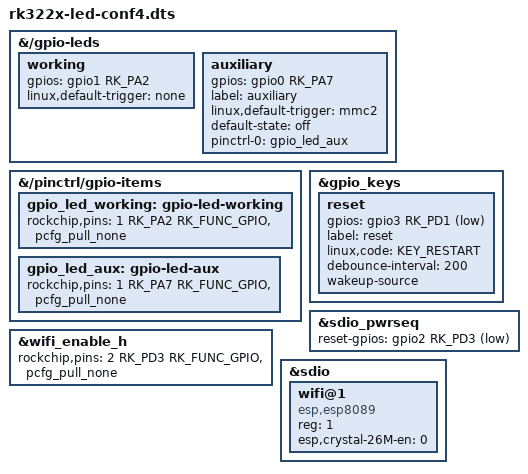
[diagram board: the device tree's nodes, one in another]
/dts-v1/;
/plugin/;

#include <dt-bindings/gpio/gpio.h>
#include <dt-bindings/input/input.h>
#include <dt-bindings/pinctrl/rockchip.h>

/ {

	fragment@0 {
		target-path = "/gpio-leds";
		__overlay__ {

			working {
				gpios = <&gpio1 RK_PA2 GPIO_ACTIVE_HIGH>;
				linux,default-trigger = "none";
			};

			auxiliary {
				gpios = <&gpio0 RK_PA7 GPIO_ACTIVE_HIGH>;
				label = "auxiliary";
				linux,default-trigger = "mmc2";
				default-state = "off";
				pinctrl-names = "default";
				pinctrl-0 = <&gpio_led_aux>;
			};

		};
	};

	fragment@1 {
		target-path = "/pinctrl/gpio-items";
		__overlay__ {

			gpio_led_working: gpio-led-working {
				rockchip,pins = <1 RK_PA2 RK_FUNC_GPIO &pcfg_pull_none>;
			};

			gpio_led_aux: gpio-led-aux {
				rockchip,pins =  <1 RK_PA7 RK_FUNC_GPIO &pcfg_pull_none>;
			};

		};
	};

	fragment@2 {
		target = <&gpio_keys>;
		__overlay__ {

			reset {
				gpios = <&gpio3 RK_PD1 GPIO_ACTIVE_LOW>;
				label = "reset";
				linux,code = <KEY_RESTART>;
				debounce-interval = <200>;
				wakeup-source;
			};

		};
	};

	fragment@3 {
		target = <&sdio_pwrseq>;
		__overlay__ {

			reset-gpios = <&gpio2 RK_PD3 GPIO_ACTIVE_LOW>; /* GPIO2_D3 */

		};

	};

	fragment@4 {
		target = <&wifi_enable_h>;
		__overlay__ {

			rockchip,pins = <2 RK_PD3 RK_FUNC_GPIO &pcfg_pull_none>;

		};

	};

	fragment@5 {
		target = <&sdio>;
		__overlay__ {
			#address-cells = <1>;
			#size-cells = <0>;

			wifi@1 {
				compatible = "esp,esp8089";
				reg = <1>;
				esp,crystal-26M-en = <0>;
			};

		};
	};

};
